# ESP32S31_RADIO register map
Vendor: Espressif; Series: ESP32-S31; File version: 3.52
Registers are 32-bit, read-write, no defined reset value unless marked. A register's access mark holds for its fields unless they carry their own. Offsets are from the block's base; [hi:lo] are bit positions; {n}, {i} and the like mark numbered series.

## WIFI_MAC_RX_RUNTIME_RESULTS — Sparse receive statistics-clear and end-result words recovered from complete hal_sniffer_rx_clr_statistics and hal_mac_rx_get_end_info leaves.
Base 0x20104E28
0x00 STATISTICS_CLEAR — Complete hal_sniffer_rx_clr_statistics pulses bit 31 high then low using a fresh read before each write.
  [31] CLEAR_PULSE
0x08 END_RESULT_LOW ro — First full result word returned by hal_mac_rx_get_end_info.
  [31:0] VALUE
0x0C END_RESULT_HIGH ro — Second full result word returned by hal_mac_rx_get_end_info.
  [31:0] VALUE

## WIFI_MAC_BSSID_POLICY — Per-interface BSSID address and policy words used by scan and associated-STA receive filtering.
Base 0x20104000
{0x0+8i} BSSID_LOW{i} (i=0..3) — BSSID bytes 0..3 for interfaces 0..3; hal_mac_set_bssid publishes a complete full-word store.
  [31:0] BYTES_0_3
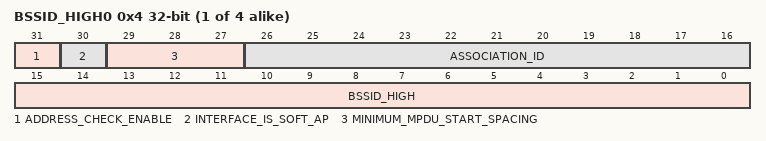
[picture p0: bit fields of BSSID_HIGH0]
{0x4+8i} BSSID_HIGH{i} (i=0..3) — Canonical high BSSID, association identity and interface policy word for interfaces 0..3. Complete dbg_read_rx_misc independently decodes every field; the HE association leaf updates the MMSS/AID fields of interface zero rather than defining a second register identity.
  [31] ADDRESS_CHECK_ENABLE — MACBSSID_EN: hal_mac_set_bssid clears this bit before changing the address and sets it after publication; the reachable associated-STA policy branch also sets it.
  [30] INTERFACE_IS_SOFT_AP — Cleared for interface zero by the associated-STA policy-five transaction.
  [29:27] MINIMUM_MPDU_START_SPACING — Three-bit MMSS value printed by dbg_read_rx_misc.
  [26:16] ASSOCIATION_ID — Eleven-bit AID printed by dbg_read_rx_misc.
  [15:0] BSSID_HIGH

## WIFI_MAC_INTERFACE_ADDRESS — Four interface-address pairs consumed by MAC receive filtering.
Base 0x2010405C
{0x0+8i} ADDRESS_LOW{i} (i=0..3) — Interface MAC bytes 0..3 in little-endian order, published by the first full-word store.
  [31:0] BYTES_0_3
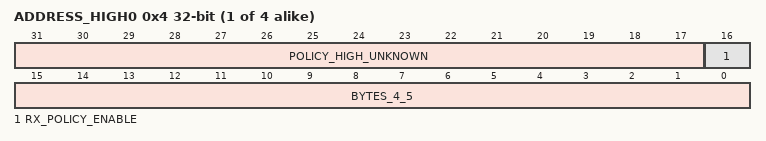
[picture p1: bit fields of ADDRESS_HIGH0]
{0x4+8i} ADDRESS_HIGH{i} (i=0..3) — Interface MAC bytes 4..5 are published as a full-word store before a separate fresh-read RMW sets receive-policy enable bit 16.
  [31:17] POLICY_HIGH_UNKNOWN
  [16] RX_POLICY_ENABLE — Set by a separate fresh-read RMW in hal_mac_set_addr and by the reachable associated-STA policy branch.
  [15:0] BYTES_4_5

## WIFI_MAC_RX_FILTER — Four WDEVRX_ABORT receive-queue policy words. Complete dbg_read_rx_misc names every used bit through 19; queue three is also the complete promiscuous-sniffer control word.
Base 0x201040D8
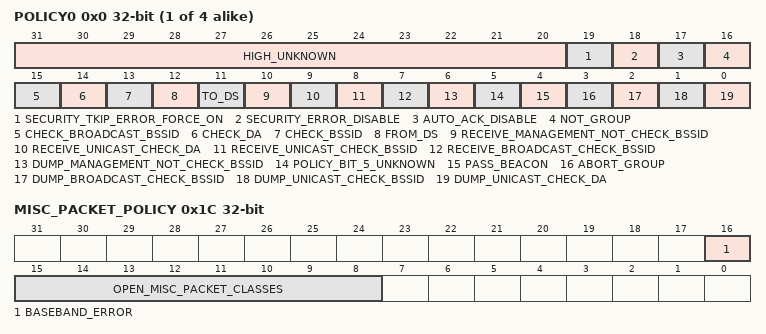
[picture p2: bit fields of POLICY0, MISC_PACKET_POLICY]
{0x0+4i} POLICY{i} (i=0..3) — WDEVRX_ABORT[0-3], updated through separate fresh-read RMW edges.
  [31:20] HIGH_UNKNOWN
  [19] SECURITY_TKIP_ERROR_FORCE_ON
  [18] SECURITY_ERROR_DISABLE
  [17] AUTO_ACK_DISABLE — Complete hal_sniffer_enable sets this bit first on queue three; the debug decoder names it AUTOACK_DISABLE.
  [16] NOT_GROUP
  [15] CHECK_BROADCAST_BSSID
  [14] CHECK_DA
  [13] CHECK_BSSID
  [12] FROM_DS
  [11] TO_DS
  [10] RECEIVE_MANAGEMENT_NOT_CHECK_BSSID
  [9] RECEIVE_UNICAST_CHECK_DA
  [8] RECEIVE_UNICAST_CHECK_BSSID — The policy-six UBSSID branch sets this bit before live vendor Authentication.
  [7] RECEIVE_BROADCAST_CHECK_BSSID
  [6] DUMP_MANAGEMENT_NOT_CHECK_BSSID
  [5] POLICY_BIT_5_UNKNOWN
  [4] PASS_BEACON
  [3] ABORT_GROUP
  [2] DUMP_BROADCAST_CHECK_BSSID
  [1] DUMP_UNICAST_CHECK_BSSID — The policy-six UBSSID branch sets this bit before live vendor Authentication.
  [0] DUMP_UNICAST_CHECK_DA
{0x10+4i} BASEBAND_ERROR_STATUS{i} (i=0..2) ro — First three words sampled by the bounded four-entry hal_ifc_get_bb_err_bitmap loop. Bit 16 contributes the corresponding output bitmap bit.
  [16] ERROR
0x1C MISC_PACKET_POLICY — The open promiscuous RX frontier sets bits 15:8 together after the complete sniffer-enable leaf. The complete vendor misc-packet leaf independently proves this register and related packet-class fields. Complete hal_ifc_get_bb_err_bitmap reads bit 16 as the fourth baseband-error status bit.
  [16] BASEBAND_ERROR ro — Fourth status bit sampled by the bounded hal_ifc_get_bb_err_bitmap loop.
  [15:8] OPEN_MISC_PACKET_CLASSES — Eight independent class-enable bits used by the working open scan/STA receive path; every eight-bit mask is representable.
